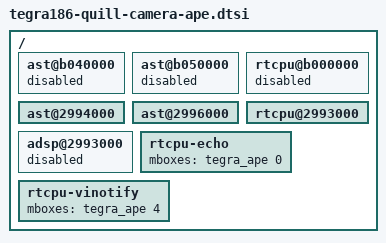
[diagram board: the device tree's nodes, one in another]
/*
 * tegra186-quill-camera-ape.dtsi: Quill APE for camera dtsi.
 *
 * Copyright (c) 2016, NVIDIA CORPORATION.  All rights reserved.
 *
 * This program is free software; you can redistribute it and/or modify
 * it under the terms of the GNU General Public License as published by
 * the Free Software Foundation; version 2 of the License.
 *
 * This program is distributed in the hope that it will be useful, but WITHOUT
 * ANY WARRANTY; without even the implied warranty of MERCHANTABILITY or
 * FITNESS FOR A PARTICULAR PURPOSE.  See the GNU General Public License for
 * more details.
 */

/ {
	ast@b040000 {
		status = "disabled";
	};

	ast@b050000 {
		status = "disabled";
	};

	rtcpu@b000000 {	/* Do not use SCE as camera-rtcpu */
		status = "disabled";
	};

	ast@2994000 {
		status = "okay";
	};

	ast@2996000 {
		status = "okay";
	};

	rtcpu@2993000 {	/* use APE as camera-rtcpu */
		status = "okay";
	};

	adsp@2993000 {	/* Do not use APE as adsp */
		status = "disabled";
	};

	rtcpu-echo {
		mboxes = <&tegra_ape 0>;
		status = "okay";
	};

	rtcpu-vinotify {
		mboxes = <&tegra_ape 4>;
		status = "okay";
	};
};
